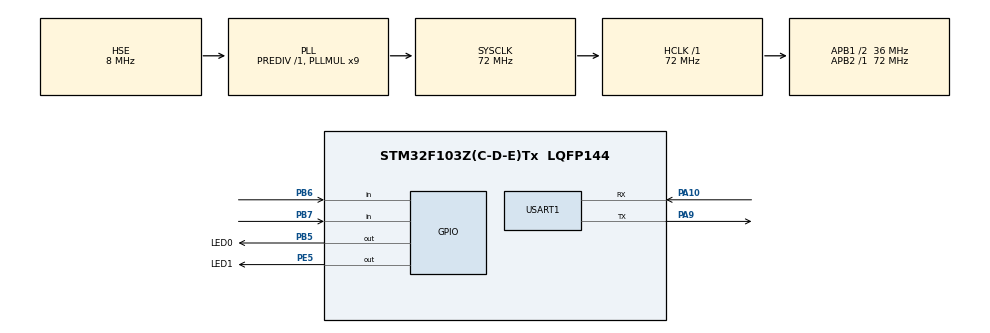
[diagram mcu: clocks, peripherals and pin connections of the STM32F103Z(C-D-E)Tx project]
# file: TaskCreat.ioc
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FREERTOS.Tasks01=defaultTask,0,128,StartDefaultTask,Default,NULL,Dynamic,NULL,NULL;LED_Blink,-3,128,LED_Task,Default,NULL,Dynamic,NULL,NULL;USART,-3,128,printf,Default,NULL,Dynamic,NULL,NULL
Mcu.Family=STM32F1
Mcu.Name=STM32F103Z(C-D-E)Tx
Mcu.Package=LQFP144
NVIC.PriorityGroup=NVIC_PRIORITYGROUP_4
NVIC.TIM1_UP_IRQn=true\:15\:0\:false\:false\:true\:false\:false\:true
NVIC.TimeBase=TIM1_UP_IRQn
NVIC.TimeBaseIP=TIM1
OSC_IN.Mode=HSE-External-Oscillator
OSC_IN.Signal=RCC_OSC_IN
OSC_OUT.Mode=HSE-External-Oscillator
OSC_OUT.Signal=RCC_OSC_OUT
PA10.Mode=Asynchronous
PA10.Signal=USART1_RX
PA13.Mode=Serial_Wire
PA13.Signal=SYS_JTMS-SWDIO
PA14.Mode=Serial_Wire
PA14.Signal=SYS_JTCK-SWCLK
PA9.Mode=Asynchronous
PA9.Signal=USART1_TX
PB5.GPIO_Label=LED0
PB5.Signal=GPIO_Output
PB6.Signal=GPIO_Input
PB7.Signal=GPIO_Input
PE5.GPIO_Label=LED1
PE5.Signal=GPIO_Output
ProjectManager.HeapSize=0x800
ProjectManager.StackSize=0x800
ProjectManager.TargetToolchain=MDK-ARM V5.32
RCC.AHBFreq_Value=72000000
RCC.APB1CLKDivider=RCC_HCLK_DIV2
RCC.APB1Freq_Value=36000000
RCC.APB1TimFreq_Value=72000000
RCC.APB2Freq_Value=72000000
RCC.APB2TimFreq_Value=72000000
RCC.HCLKFreq_Value=72000000
RCC.PLLMUL=RCC_PLL_MUL9
RCC.PLLSourceVirtual=RCC_PLLSOURCE_HSE
RCC.SYSCLKFreq_VALUE=72000000
RCC.SYSCLKSource=RCC_SYSCLKSOURCE_PLLCLK
RCC.USBFreq_Value=72000000
USART1.VirtualMode=VM_ASYNC
VP_FREERTOS_VS_CMSIS_V1.Mode=CMSIS_V1
VP_SYS_VS_tim1.Mode=TIM1
board=custom

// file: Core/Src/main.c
/* USER CODE BEGIN Header */
/**
  ******************************************************************************
  * @file           : main.c
  * @brief          : Main program body
  ******************************************************************************
  * @attention
  *
  * <h2><center>&copy; Copyright (c) 2021 STMicroelectronics.
  * All rights reserved.</center></h2>
  *
  * This software component is licensed by ST under Ultimate Liberty license
  * SLA0044, the "License"; You may not use this file except in compliance with
  * the License. You may obtain a copy of the License at:
  *                             www.st.com/SLA0044
  *
  ******************************************************************************
  */
/* USER CODE END Header */
#include "main.h"
#include "cmsis_os.h"
#include "usart.h"
#include "gpio.h"

void SystemClock_Config(void);
void MX_FREERTOS_Init(void);

int main(void)
{

  /* MCU Configuration--------------------------------------------------------*/

  /* Reset of all peripherals, Initializes the Flash interface and the Systick. */
  HAL_Init();

  /* Configure the system clock */
  SystemClock_Config();

  /* Initialize all configured peripherals */
  MX_GPIO_Init();
  MX_USART1_UART_Init();

  /* Call init function for freertos objects (in freertos.c) */
  MX_FREERTOS_Init();
  /* Start scheduler */
  osKernelStart();

  /* We should never get here as control is now taken by the scheduler */
  /* Infinite loop */
  while (1)
  {

  }
}

void SystemClock_Config(void)
{
  RCC_OscInitTypeDef RCC_OscInitStruct = {0};
  RCC_ClkInitTypeDef RCC_ClkInitStruct = {0};

  /** Initializes the RCC Oscillators according to the specified parameters
  * in the RCC_OscInitTypeDef structure.
  */
  RCC_OscInitStruct.OscillatorType = RCC_OSCILLATORTYPE_HSE;
  RCC_OscInitStruct.HSEState = RCC_HSE_ON;
  RCC_OscInitStruct.HSEPredivValue = RCC_HSE_PREDIV_DIV1;
  RCC_OscInitStruct.HSIState = RCC_HSI_ON;
  RCC_OscInitStruct.PLL.PLLState = RCC_PLL_ON;
  RCC_OscInitStruct.PLL.PLLSource = RCC_PLLSOURCE_HSE;
  RCC_OscInitStruct.PLL.PLLMUL = RCC_PLL_MUL9;
  if (HAL_RCC_OscConfig(&RCC_OscInitStruct) != HAL_OK)
  {
    Error_Handler();
  }
  /** Initializes the CPU, AHB and APB buses clocks
  */
  RCC_ClkInitStruct.ClockType = RCC_CLOCKTYPE_HCLK|RCC_CLOCKTYPE_SYSCLK
                              |RCC_CLOCKTYPE_PCLK1|RCC_CLOCKTYPE_PCLK2;
  RCC_ClkInitStruct.SYSCLKSource = RCC_SYSCLKSOURCE_PLLCLK;
  RCC_ClkInitStruct.AHBCLKDivider = RCC_SYSCLK_DIV1;
  RCC_ClkInitStruct.APB1CLKDivider = RCC_HCLK_DIV2;
  RCC_ClkInitStruct.APB2CLKDivider = RCC_HCLK_DIV1;

  if (HAL_RCC_ClockConfig(&RCC_ClkInitStruct, FLASH_LATENCY_2) != HAL_OK)
  {
    Error_Handler();
  }
}

void HAL_TIM_PeriodElapsedCallback(TIM_HandleTypeDef *htim)
{
  if (htim->Instance == TIM1) {
    HAL_IncTick();
  }
}

void Error_Handler(void)
{
  __disable_irq();
  while (1)
  {
  }
}

/************************ (C) COPYRIGHT STMicroelectronics *****END OF FILE****/

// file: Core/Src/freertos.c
/* USER CODE BEGIN Header */
/**
  ******************************************************************************
  * File Name          : freertos.c
  * Description        : Code for freertos applications
  ******************************************************************************
  * @attention
  *
  * <h2><center>&copy; Copyright (c) 2021 STMicroelectronics.
  * All rights reserved.</center></h2>
  *
  * This software component is licensed by ST under Ultimate Liberty license
  * SLA0044, the "License"; You may not use this file except in compliance with
  * the License. You may obtain a copy of the License at:
  *                             www.st.com/SLA0044
  *
  ******************************************************************************
  */
/* USER CODE END Header */

#include "FreeRTOS.h"
#include "task.h"
#include "main.h"
#include "cmsis_os.h"

osThreadId defaultTaskHandle;
osThreadId LED_BlinkHandle;
osThreadId USARTHandle;

void StartDefaultTask(void const * argument);
void LED_Task(void const * argument);
void printf(void const * argument);

void MX_FREERTOS_Init(void); /* (MISRA C 2004 rule 8.1) */

/* GetIdleTaskMemory prototype (linked to static allocation support) */
void vApplicationGetIdleTaskMemory( StaticTask_t **ppxIdleTaskTCBBuffer, StackType_t **ppxIdleTaskStackBuffer, uint32_t *pulIdleTaskStackSize );

/* USER CODE BEGIN GET_IDLE_TASK_MEMORY */
static StaticTask_t xIdleTaskTCBBuffer;
static StackType_t xIdleStack[configMINIMAL_STACK_SIZE];

void vApplicationGetIdleTaskMemory( StaticTask_t **ppxIdleTaskTCBBuffer, StackType_t **ppxIdleTaskStackBuffer, uint32_t *pulIdleTaskStackSize )
{
  *ppxIdleTaskTCBBuffer = &xIdleTaskTCBBuffer;
  *ppxIdleTaskStackBuffer = &xIdleStack[0];
  *pulIdleTaskStackSize = configMINIMAL_STACK_SIZE;
  /* place for user code */
}
/* USER CODE END GET_IDLE_TASK_MEMORY */

void MX_FREERTOS_Init(void) {

  /* Create the thread(s) */
  /* definition and creation of defaultTask */
  osThreadDef(defaultTask, StartDefaultTask, osPriorityNormal, 0, 128);
  defaultTaskHandle = osThreadCreate(osThread(defaultTask), NULL);

  /* definition and creation of LED_Blink */
  osThreadDef(LED_Blink, LED_Task, osPriorityIdle, 0, 128);
  LED_BlinkHandle = osThreadCreate(osThread(LED_Blink), NULL);

  /* definition and creation of USART */
  osThreadDef(USART, printf, osPriorityIdle, 0, 128);
  USARTHandle = osThreadCreate(osThread(USART), NULL);

}

void StartDefaultTask(void const * argument)
{
  /* USER CODE BEGIN StartDefaultTask */
  /* Infinite loop */
  for(;;)
  {
    HAL_GPIO_WritePin(LED1_GPIO_Port,LED1_Pin,GPIO_PIN_RESET);
    osDelay(100);
    HAL_GPIO_WritePin(LED1_GPIO_Port,LED1_Pin,GPIO_PIN_SET);
    osDelay(100);
  }
  /* USER CODE END StartDefaultTask */
}

void LED_Task(void const * argument)
{
  /* USER CODE BEGIN LED_Task */
  /* Infinite loop */
  for(;;)
  {
    HAL_GPIO_WritePin(LED0_GPIO_Port,LED0_Pin,GPIO_PIN_RESET);
    osDelay(500);
    HAL_GPIO_WritePin(LED0_GPIO_Port,LED0_Pin,GPIO_PIN_SET);
    osDelay(500);
  }
  /* USER CODE END LED_Task */
}

void printf(void const * argument)
{
  for(;;)
  {
    osDelay(1);
  }
}

/************************ (C) COPYRIGHT STMicroelectronics *****END OF FILE****/
